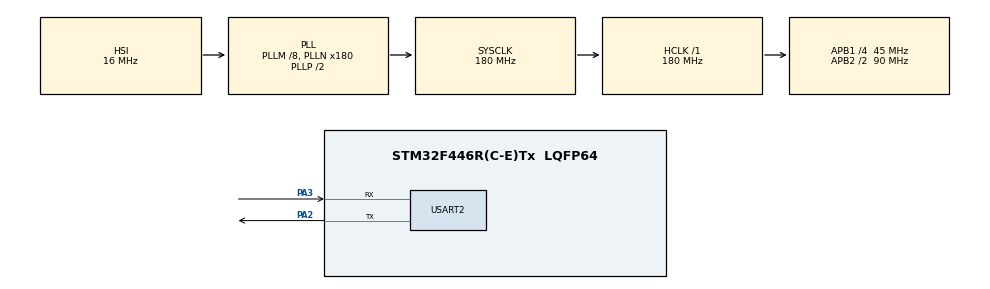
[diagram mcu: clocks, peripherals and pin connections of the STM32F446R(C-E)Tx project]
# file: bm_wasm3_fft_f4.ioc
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Mcu.Family=STM32F4
Mcu.Name=STM32F446R(C-E)Tx
Mcu.Package=LQFP64
NVIC.PriorityGroup=NVIC_PRIORITYGROUP_4
PA2.Mode=Asynchronous
PA2.Signal=USART2_TX
PA3.Mode=Asynchronous
PA3.Signal=USART2_RX
ProjectManager.HeapSize=0x200
ProjectManager.StackSize=0x400
ProjectManager.TargetToolchain=STM32CubeIDE
RCC.AHBFreq_Value=180000000
RCC.APB1CLKDivider=RCC_HCLK_DIV4
RCC.APB1Freq_Value=45000000
RCC.APB1TimFreq_Value=90000000
RCC.APB2CLKDivider=RCC_HCLK_DIV2
RCC.APB2Freq_Value=90000000
RCC.APB2TimFreq_Value=180000000
RCC.CortexFreq_Value=180000000
RCC.HCLKFreq_Value=180000000
RCC.PLLM=8
RCC.PLLN=180
RCC.SYSCLKFreq_VALUE=180000000
RCC.SYSCLKSource=RCC_SYSCLKSOURCE_PLLCLK
RCC.USBFreq_Value=180000000
RCC.VCOOutputFreq_Value=360000000
USART2.VirtualMode=VM_ASYNC
board=custom

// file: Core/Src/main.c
/* USER CODE BEGIN Header */
/**
 ******************************************************************************
 * @file           : main.c
 * @brief          : Main program body
 ******************************************************************************
 * @attention
 *
 * Copyright (c) 2025 STMicroelectronics.
 * All rights reserved.
 *
 * This software is licensed under terms that can be found in the LICENSE file
 * in the root directory of this software component.
 * If no LICENSE file comes with this software, it is provided AS-IS.
 *
 ******************************************************************************
 */
/* USER CODE END Header */
#include "main.h"

/* USER CODE BEGIN Includes */
#if __has_include(<wasm3.h>)
#include <wasm3.h>
#elif __has_include(<m3/wasm3.h>)
#include <m3/wasm3.h>
#else
#include "wasm3.h"
#endif

#if __has_include(<m3_api_defs.h>)
#include <m3_api_defs.h>
#elif __has_include(<m3/m3_api_defs.h>)
#include <m3/m3_api_defs.h>
#else
#include "m3_api_defs.h"
#endif

#include "fft_bench.wasm.h"
/* USER CODE END Includes */

/* USER CODE BEGIN PD */
#define NUM_ITER  100
/* USER CODE END PD */

UART_HandleTypeDef huart2;

/* USER CODE BEGIN PV */
volatile uint32_t total_cycles_wasm = 0;
volatile uint32_t avg_cycles_wasm   = 0;

/* USER CODE END PV */

void SystemClock_Config(void);
static void MX_GPIO_Init(void);
static void MX_USART2_UART_Init(void);

/* USER CODE BEGIN 0 */
static void DWT_Init(void) {
	CoreDebug->DEMCR |= CoreDebug_DEMCR_TRCENA_Msk; // abilita DWT
	DWT->CYCCNT = 0;
	DWT->CTRL |= DWT_CTRL_CYCCNTENA_Msk;
}

static void wasm_panic(const char* where, M3Result r) {
    // Usa printf se hai il retarget via UART,
    // altrimenti metti un breakpoint qui e guarda 'where' e 'r' in debug
    printf("Wasm error in %s: %s\r\n", where, r);
    __disable_irq();
    while (1) {}
}

static void run_wasm_fft_benchmark(void) {
	M3Result r;

	IM3Environment env = m3_NewEnvironment();
	if (!env) wasm_panic("m3_NewEnvironment", "OOM");

	IM3Runtime rt = m3_NewRuntime(env, 1024, NULL);
	if (!rt) wasm_panic("m3_NewRuntime", "OOM");

	IM3Module mod = NULL;
	r = m3_ParseModule(env, &mod,
			(const uint8_t*)fft_bench_wasm,
			fft_bench_wasm_len);
	if (r) wasm_panic("m3_ParseModule", r);

	r = m3_LoadModule(rt, mod);
	if (r) wasm_panic("m3_LoadModule", r);

	// Il modulo FFT non ha import host, quindi niente m3_LinkRawFunction

	IM3Function fn_init = NULL;
	IM3Function fn_bench = NULL;

	r = m3_FindFunction(&fn_init, rt, "fft_init");
	if (r || !fn_init) wasm_panic("m3_FindFunction(fft_init)", r);

	r = m3_FindFunction(&fn_bench, rt, "fft_bench");
	if (r || !fn_bench) wasm_panic("m3_FindFunction(fft_bench)", r);

	// Inizializzazione DWT e disabilitazione SysTick/IRQ per confronto pulito
	DWT_Init();
	SysTick->CTRL = 0;    // disabilita SysTick (come nei test nativi)

	// Inizializza il buffer dentro il modulo Wasm
	r = m3_CallV(fn_init);
	if (r) wasm_panic("m3_CallV(init_buffer)", r);

	__disable_irq();

	uint32_t start = DWT->CYCCNT;

	// bench(NUM_ITER) dentro Wasm
	r = m3_CallV(fn_bench, (uint32_t)NUM_ITER);
	if (r) {
		__enable_irq();
		wasm_panic("m3_CallV(bench)", r);
	}

	uint32_t end = DWT->CYCCNT;

	__enable_irq();

	total_cycles_wasm = end - start;
	avg_cycles_wasm   = total_cycles_wasm / NUM_ITER;
	printf("Baremetal + wasm3\r\n");
	printf("Total cycles: %lu\r\n", (unsigned long)total_cycles_wasm);
	printf("Avg cycles per FFT: %lu\r\n", (unsigned long)avg_cycles_wasm);

	// cleanup opzionale (tanto poi non usciamo da main)
	m3_FreeRuntime(rt);
	m3_FreeEnvironment(env);
}

int _write(int file, char *ptr, int len)
{
	HAL_UART_Transmit(&huart2, (uint8_t*)ptr, len, HAL_MAX_DELAY);
	return len;
}
/* USER CODE END 0 */

int main(void)
{

	/* MCU Configuration--------------------------------------------------------*/

	/* Reset of all peripherals, Initializes the Flash interface and the Systick. */
	HAL_Init();

	/* Configure the system clock */
	SystemClock_Config();

	/* Initialize all configured peripherals */
	MX_GPIO_Init();
	MX_USART2_UART_Init();
	/* USER CODE BEGIN 2 */

	run_wasm_fft_benchmark();   // misura in wasm3
	/* USER CODE END 2 */

	/* Infinite loop */
	while (1)
	{

		/* USER CODE BEGIN 3 */
		__NOP();
	}
	/* USER CODE END 3 */
}

void SystemClock_Config(void)
{
	RCC_OscInitTypeDef RCC_OscInitStruct = {0};
	RCC_ClkInitTypeDef RCC_ClkInitStruct = {0};

	/** Configure the main internal regulator output voltage
	 */
	__HAL_RCC_PWR_CLK_ENABLE();
	__HAL_PWR_VOLTAGESCALING_CONFIG(PWR_REGULATOR_VOLTAGE_SCALE1);

	/** Initializes the RCC Oscillators according to the specified parameters
	 * in the RCC_OscInitTypeDef structure.
	 */
	RCC_OscInitStruct.OscillatorType = RCC_OSCILLATORTYPE_HSI;
	RCC_OscInitStruct.HSIState = RCC_HSI_ON;
	RCC_OscInitStruct.HSICalibrationValue = RCC_HSICALIBRATION_DEFAULT;
	RCC_OscInitStruct.PLL.PLLState = RCC_PLL_ON;
	RCC_OscInitStruct.PLL.PLLSource = RCC_PLLSOURCE_HSI;
	RCC_OscInitStruct.PLL.PLLM = 8;
	RCC_OscInitStruct.PLL.PLLN = 180;
	RCC_OscInitStruct.PLL.PLLP = RCC_PLLP_DIV2;
	RCC_OscInitStruct.PLL.PLLQ = 2;
	RCC_OscInitStruct.PLL.PLLR = 2;
	if (HAL_RCC_OscConfig(&RCC_OscInitStruct) != HAL_OK)
	{
		Error_Handler();
	}

	/** Activate the Over-Drive mode
	 */
	if (HAL_PWREx_EnableOverDrive() != HAL_OK)
	{
		Error_Handler();
	}

	/** Initializes the CPU, AHB and APB buses clocks
	 */
	RCC_ClkInitStruct.ClockType = RCC_CLOCKTYPE_HCLK|RCC_CLOCKTYPE_SYSCLK
			|RCC_CLOCKTYPE_PCLK1|RCC_CLOCKTYPE_PCLK2;
	RCC_ClkInitStruct.SYSCLKSource = RCC_SYSCLKSOURCE_PLLCLK;
	RCC_ClkInitStruct.AHBCLKDivider = RCC_SYSCLK_DIV1;
	RCC_ClkInitStruct.APB1CLKDivider = RCC_HCLK_DIV4;
	RCC_ClkInitStruct.APB2CLKDivider = RCC_HCLK_DIV2;

	if (HAL_RCC_ClockConfig(&RCC_ClkInitStruct, FLASH_LATENCY_5) != HAL_OK)
	{
		Error_Handler();
	}
}

static void MX_USART2_UART_Init(void)
{

	huart2.Instance = USART2;
	huart2.Init.BaudRate = 115200;
	huart2.Init.WordLength = UART_WORDLENGTH_8B;
	huart2.Init.StopBits = UART_STOPBITS_1;
	huart2.Init.Parity = UART_PARITY_NONE;
	huart2.Init.Mode = UART_MODE_TX_RX;
	huart2.Init.HwFlowCtl = UART_HWCONTROL_NONE;
	huart2.Init.OverSampling = UART_OVERSAMPLING_16;
	if (HAL_UART_Init(&huart2) != HAL_OK)
	{
		Error_Handler();
	}

}

static void MX_GPIO_Init(void)
{

	/* GPIO Ports Clock Enable */
	__HAL_RCC_GPIOA_CLK_ENABLE();

}

void Error_Handler(void)
{
	__disable_irq();
	while (1)
	{
	}
}
